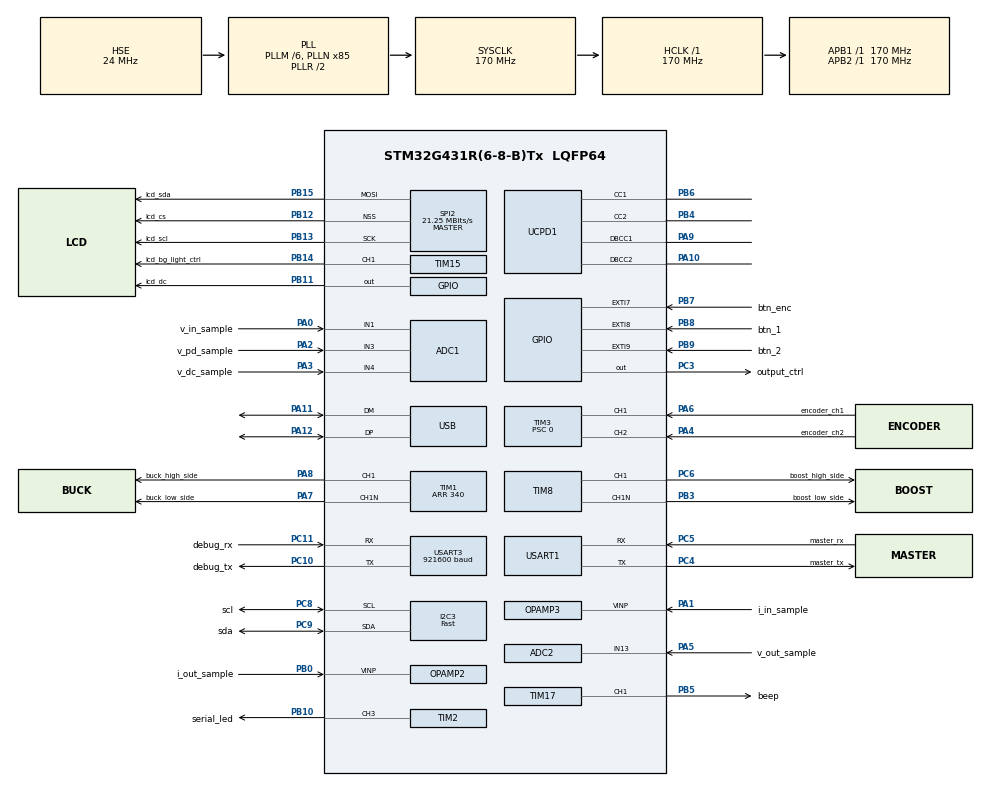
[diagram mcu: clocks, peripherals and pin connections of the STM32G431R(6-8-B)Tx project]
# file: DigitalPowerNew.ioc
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ADC1.Channel-2\#ChannelRegularConversion=ADC_CHANNEL_1
ADC1.Channel-3\#ChannelRegularConversion=ADC_CHANNEL_3
ADC1.Channel-4\#ChannelRegularConversion=ADC_CHANNEL_4
ADC1.ContinuousConvMode=ENABLE
ADC1.DMAContinuousRequests=ENABLE
ADC1.DataAlign=ADC_DATAALIGN_RIGHT
ADC1.EOCSelection=ADC_EOC_SEQ_CONV
ADC1.NbrOfConversion=3
ADC1.NbrOfConversionFlag=1
ADC1.OffsetNumber-2\#ChannelRegularConversion=ADC_OFFSET_NONE
ADC1.OffsetNumber-3\#ChannelRegularConversion=ADC_OFFSET_NONE
ADC1.OffsetNumber-4\#ChannelRegularConversion=ADC_OFFSET_NONE
ADC1.OversamplingMode=ENABLE
ADC1.Rank-2\#ChannelRegularConversion=1
ADC1.Rank-3\#ChannelRegularConversion=2
ADC1.Rank-4\#ChannelRegularConversion=3
ADC1.Ratio=ADC_OVERSAMPLING_RATIO_16
ADC1.RightBitShift=ADC_RIGHTBITSHIFT_NONE
ADC1.SamplingTime-2\#ChannelRegularConversion=ADC_SAMPLETIME_24CYCLES_5
ADC1.SamplingTime-3\#ChannelRegularConversion=ADC_SAMPLETIME_24CYCLES_5
ADC1.SamplingTime-4\#ChannelRegularConversion=ADC_SAMPLETIME_24CYCLES_5
ADC1.master=1
ADC2.Channel-1\#ChannelRegularConversion=ADC_CHANNEL_13
ADC2.Channel-2\#ChannelRegularConversion=ADC_CHANNEL_VOPAMP2
ADC2.Channel-3\#ChannelRegularConversion=ADC_CHANNEL_VOPAMP3_ADC2
ADC2.ClockPrescaler=ADC_CLOCK_SYNC_PCLK_DIV4
ADC2.ContinuousConvMode=ENABLE
ADC2.DMAContinuousRequests=ENABLE
ADC2.DataAlign=ADC_DATAALIGN_RIGHT
ADC2.EOCSelection=ADC_EOC_SEQ_CONV
ADC2.NbrOfConversion=3
ADC2.NbrOfConversionFlag=1
ADC2.OffsetNumber-1\#ChannelRegularConversion=ADC_OFFSET_NONE
ADC2.OffsetNumber-2\#ChannelRegularConversion=ADC_OFFSET_NONE
ADC2.OffsetNumber-3\#ChannelRegularConversion=ADC_OFFSET_NONE
ADC2.OversamplingMode=ENABLE
ADC2.Rank-1\#ChannelRegularConversion=1
ADC2.Rank-2\#ChannelRegularConversion=2
ADC2.Rank-3\#ChannelRegularConversion=3
ADC2.Ratio=ADC_OVERSAMPLING_RATIO_16
ADC2.RightBitShift=ADC_RIGHTBITSHIFT_NONE
ADC2.SamplingTime-1\#ChannelRegularConversion=ADC_SAMPLETIME_24CYCLES_5
ADC2.SamplingTime-2\#ChannelRegularConversion=ADC_SAMPLETIME_24CYCLES_5
ADC2.SamplingTime-3\#ChannelRegularConversion=ADC_SAMPLETIME_24CYCLES_5
DAC1.DAC_Channel-DAC_OUT2_Int=DAC_CHANNEL_2
DAC3.DAC_Channel-DAC_OUT2_Int=DAC_CHANNEL_2
Dma.ADC1.1.Direction=DMA_PERIPH_TO_MEMORY
Dma.ADC1.1.EventEnable=DISABLE
Dma.ADC1.1.Instance=DMA1_Channel2
Dma.ADC1.1.MemDataAlignment=DMA_MDATAALIGN_HALFWORD
Dma.ADC1.1.MemInc=DMA_MINC_ENABLE
Dma.ADC1.1.Mode=DMA_CIRCULAR
Dma.ADC1.1.PeriphDataAlignment=DMA_PDATAALIGN_HALFWORD
Dma.ADC1.1.PeriphInc=DMA_PINC_DISABLE
Dma.ADC1.1.Polarity=HAL_DMAMUX_REQ_GEN_RISING
Dma.ADC1.1.Priority=DMA_PRIORITY_LOW
Dma.ADC1.1.RequestNumber=1
Dma.ADC1.1.SignalID=NONE
Dma.ADC1.1.SyncEnable=DISABLE
Dma.ADC1.1.SyncPolarity=HAL_DMAMUX_SYNC_NO_EVENT
Dma.ADC1.1.SyncRequestNumber=1
Dma.ADC1.1.SyncSignalID=NONE
Dma.ADC2.2.Direction=DMA_PERIPH_TO_MEMORY
Dma.ADC2.2.EventEnable=DISABLE
Dma.ADC2.2.Instance=DMA1_Channel3
Dma.ADC2.2.MemDataAlignment=DMA_MDATAALIGN_HALFWORD
Dma.ADC2.2.MemInc=DMA_MINC_ENABLE
Dma.ADC2.2.Mode=DMA_CIRCULAR
Dma.ADC2.2.PeriphDataAlignment=DMA_PDATAALIGN_HALFWORD
Dma.ADC2.2.PeriphInc=DMA_PINC_DISABLE
Dma.ADC2.2.Polarity=HAL_DMAMUX_REQ_GEN_RISING
Dma.ADC2.2.Priority=DMA_PRIORITY_LOW
Dma.ADC2.2.RequestNumber=1
Dma.ADC2.2.SignalID=NONE
Dma.ADC2.2.SyncEnable=DISABLE
Dma.ADC2.2.SyncPolarity=HAL_DMAMUX_SYNC_NO_EVENT
Dma.ADC2.2.SyncRequestNumber=1
Dma.ADC2.2.SyncSignalID=NONE
Dma.Request0=TIM2_CH3
Dma.Request1=ADC1
Dma.Request2=ADC2
Dma.Request3=UCPD1_RX
Dma.Request4=UCPD1_TX
Dma.Request5=SPI2_TX
Dma.Request6=USART3_TX
Dma.SPI2_TX.5.Direction=DMA_MEMORY_TO_PERIPH
Dma.SPI2_TX.5.EventEnable=DISABLE
Dma.SPI2_TX.5.Instance=DMA1_Channel6
Dma.SPI2_TX.5.MemDataAlignment=DMA_MDATAALIGN_BYTE
Dma.SPI2_TX.5.MemInc=DMA_MINC_ENABLE
Dma.SPI2_TX.5.Mode=DMA_NORMAL
Dma.SPI2_TX.5.PeriphDataAlignment=DMA_PDATAALIGN_BYTE
Dma.SPI2_TX.5.PeriphInc=DMA_PINC_DISABLE
Dma.SPI2_TX.5.Polarity=HAL_DMAMUX_REQ_GEN_RISING
Dma.SPI2_TX.5.Priority=DMA_PRIORITY_LOW
Dma.SPI2_TX.5.RequestNumber=1
Dma.SPI2_TX.5.SignalID=NONE
Dma.SPI2_TX.5.SyncEnable=DISABLE
Dma.SPI2_TX.5.SyncPolarity=HAL_DMAMUX_SYNC_NO_EVENT
Dma.SPI2_TX.5.SyncRequestNumber=1
Dma.SPI2_TX.5.SyncSignalID=NONE
Dma.TIM2_CH3.0.Direction=DMA_MEMORY_TO_PERIPH
Dma.TIM2_CH3.0.EventEnable=DISABLE
Dma.TIM2_CH3.0.Instance=DMA1_Channel1
Dma.TIM2_CH3.0.MemDataAlignment=DMA_MDATAALIGN_HALFWORD
Dma.TIM2_CH3.0.MemInc=DMA_MINC_ENABLE
Dma.TIM2_CH3.0.Mode=DMA_NORMAL
Dma.TIM2_CH3.0.PeriphDataAlignment=DMA_PDATAALIGN_WORD
Dma.TIM2_CH3.0.PeriphInc=DMA_PINC_DISABLE
Dma.TIM2_CH3.0.Polarity=HAL_DMAMUX_REQ_GEN_RISING
Dma.TIM2_CH3.0.Priority=DMA_PRIORITY_LOW
Dma.TIM2_CH3.0.RequestNumber=1
Dma.TIM2_CH3.0.SignalID=NONE
Dma.TIM2_CH3.0.SyncEnable=DISABLE
Dma.TIM2_CH3.0.SyncPolarity=HAL_DMAMUX_SYNC_NO_EVENT
Dma.TIM2_CH3.0.SyncRequestNumber=1
Dma.TIM2_CH3.0.SyncSignalID=NONE
Dma.UCPD1_RX.3.Direction=DMA_PERIPH_TO_MEMORY
Dma.UCPD1_RX.3.EventEnable=DISABLE
Dma.UCPD1_RX.3.Instance=DMA1_Channel4
Dma.UCPD1_RX.3.MemDataAlignment=DMA_MDATAALIGN_BYTE
Dma.UCPD1_RX.3.MemInc=DMA_MINC_ENABLE
Dma.UCPD1_RX.3.Mode=DMA_NORMAL
Dma.UCPD1_RX.3.PeriphDataAlignment=DMA_PDATAALIGN_BYTE
Dma.UCPD1_RX.3.PeriphInc=DMA_PINC_DISABLE
Dma.UCPD1_RX.3.Polarity=HAL_DMAMUX_REQ_GEN_RISING
Dma.UCPD1_RX.3.Priority=DMA_PRIORITY_LOW
Dma.UCPD1_RX.3.RequestNumber=1
Dma.UCPD1_RX.3.SignalID=NONE
Dma.UCPD1_RX.3.SyncEnable=DISABLE
Dma.UCPD1_RX.3.SyncPolarity=HAL_DMAMUX_SYNC_NO_EVENT
Dma.UCPD1_RX.3.SyncRequestNumber=1
Dma.UCPD1_RX.3.SyncSignalID=NONE
Dma.UCPD1_TX.4.Direction=DMA_MEMORY_TO_PERIPH
Dma.UCPD1_TX.4.EventEnable=DISABLE
Dma.UCPD1_TX.4.Instance=DMA1_Channel5
Dma.UCPD1_TX.4.MemDataAlignment=DMA_MDATAALIGN_BYTE
Dma.UCPD1_TX.4.MemInc=DMA_MINC_ENABLE
Dma.UCPD1_TX.4.Mode=DMA_NORMAL
Dma.UCPD1_TX.4.PeriphDataAlignment=DMA_PDATAALIGN_BYTE
Dma.UCPD1_TX.4.PeriphInc=DMA_PINC_DISABLE
Dma.UCPD1_TX.4.Polarity=HAL_DMAMUX_REQ_GEN_RISING
Dma.UCPD1_TX.4.Priority=DMA_PRIORITY_LOW
Dma.UCPD1_TX.4.RequestNumber=1
Dma.UCPD1_TX.4.SignalID=NONE
Dma.UCPD1_TX.4.SyncEnable=DISABLE
Dma.UCPD1_TX.4.SyncPolarity=HAL_DMAMUX_SYNC_NO_EVENT
Dma.UCPD1_TX.4.SyncRequestNumber=1
Dma.UCPD1_TX.4.SyncSignalID=NONE
Dma.USART3_TX.6.Direction=DMA_MEMORY_TO_PERIPH
Dma.USART3_TX.6.EventEnable=DISABLE
Dma.USART3_TX.6.Instance=DMA2_Channel1
Dma.USART3_TX.6.MemDataAlignment=DMA_MDATAALIGN_BYTE
Dma.USART3_TX.6.MemInc=DMA_MINC_ENABLE
Dma.USART3_TX.6.Mode=DMA_NORMAL
Dma.USART3_TX.6.PeriphDataAlignment=DMA_PDATAALIGN_BYTE
Dma.USART3_TX.6.PeriphInc=DMA_PINC_DISABLE
Dma.USART3_TX.6.Polarity=HAL_DMAMUX_REQ_GEN_RISING
Dma.USART3_TX.6.Priority=DMA_PRIORITY_LOW
Dma.USART3_TX.6.RequestNumber=1
Dma.USART3_TX.6.SignalID=NONE
Dma.USART3_TX.6.SyncEnable=DISABLE
Dma.USART3_TX.6.SyncPolarity=HAL_DMAMUX_SYNC_NO_EVENT
Dma.USART3_TX.6.SyncRequestNumber=1
Dma.USART3_TX.6.SyncSignalID=NONE
FREERTOS.HEAP_NUMBER=3
FREERTOS.MEMORY_ALLOCATION=1
FREERTOS.Queues01=consoleBufferQueue,512,char,0,Static,consoleBufferQueueBuffer,consoleBufferQueueControlBlock;uiInputEventQueue,32,uint8_t,0,Static,uiInputEventQueueBuffer,uiInputEventQueueControlBlock
FREERTOS.Tasks01=userMain,8,256,user_main,As weak,NULL,Static,userMainBuffer,userMainControlBlock;guiThread,8,1024,gui_thread,As external,NULL,Static,guiThreadBuffer,guiThreadControlBlock;usbThread,8,512,usb_thread,As external,NULL,Static,usbThreadBuffer,usbThreadControlBlock
FREERTOS.Timers01=powerControlTimer,power_control_timer_handle,osTimerPeriodic,As external,NULL,Static,powerControlTimerControlBlock
FREERTOS.configCHECK_FOR_STACK_OVERFLOW=2
FREERTOS.configENABLE_FPU=1
FREERTOS.configLIBRARY_MAX_SYSCALL_INTERRUPT_PRIORITY=3
FREERTOS.configTIMER_TASK_PRIORITY=55
FREERTOS.copyHeapFile=1
I2C3.DualAddressMode=I2C_DUALADDRESS_DISABLE
I2C3.I2C_Speed_Mode=I2C_Fast
I2C3.Timing=0x40621236
Mcu.Family=STM32G4
Mcu.Name=STM32G431R(6-8-B)Tx
Mcu.Package=LQFP64
NVIC.DMA1_Channel1_IRQn=true\:3\:0\:false\:false\:true\:true\:false\:true\:true
NVIC.DMA1_Channel2_IRQn=true\:3\:0\:false\:false\:true\:true\:false\:true\:true
NVIC.DMA1_Channel3_IRQn=true\:3\:0\:false\:false\:true\:true\:false\:true\:true
NVIC.DMA1_Channel4_IRQn=true\:3\:0\:false\:false\:true\:true\:false\:true\:true
NVIC.DMA1_Channel5_IRQn=true\:3\:0\:false\:false\:true\:true\:false\:true\:true
NVIC.DMA1_Channel6_IRQn=true\:3\:0\:false\:false\:true\:true\:false\:true\:true
NVIC.DMA2_Channel1_IRQn=true\:3\:0\:false\:false\:true\:true\:false\:true\:true
NVIC.EXTI9_5_IRQn=true\:3\:0\:false\:false\:true\:true\:true\:true\:true
NVIC.I2C3_ER_IRQn=true\:3\:0\:false\:false\:true\:true\:true\:true\:true
NVIC.I2C3_EV_IRQn=true\:3\:0\:false\:false\:true\:true\:true\:true\:true
NVIC.PriorityGroup=NVIC_PRIORITYGROUP_4
NVIC.TIM1_UP_TIM16_IRQn=true\:3\:0\:false\:false\:true\:true\:true\:true\:true
NVIC.TIM3_IRQn=true\:3\:0\:false\:false\:true\:true\:true\:true\:true
NVIC.TIM6_DAC_IRQn=true\:3\:0\:false\:false\:true\:true\:true\:true\:true
NVIC.TIM7_IRQn=true\:15\:0\:false\:false\:true\:false\:false\:true\:true
NVIC.TimeBase=TIM7_IRQn
NVIC.TimeBaseIP=TIM7
NVIC.UCPD1_IRQn=true\:3\:0\:false\:false\:true\:true\:true\:false\:true
NVIC.USART1_IRQn=true\:3\:0\:false\:false\:true\:true\:true\:true\:true
NVIC.USART3_IRQn=true\:3\:0\:false\:false\:true\:true\:true\:true\:true
NVIC.USB_LP_IRQn=true\:3\:0\:false\:false\:true\:true\:false\:true\:true
OPAMP2.PowerMode=OPAMP_POWERMODE_HIGHSPEED
OPAMP3.PowerMode=OPAMP_POWERMODE_HIGHSPEED
PA0.GPIO_Label=v_in_sample
PA0.Mode=IN1-Single-Ended
PA0.Signal=ADC1_IN1
PA1.GPIO_Label=i_in_sample
PA1.Mode=PGA_Internally_Connected
PA1.Signal=OPAMP3_VINP
PA10.Mode=EnableDeadBattery
PA10.Signal=UCPD1_DBCC2
PA11.Mode=Device
PA11.Signal=USB_DM
PA12.Mode=Device
PA12.Signal=USB_DP
PA13.Mode=Serial_Wire
PA13.Signal=SYS_JTMS-SWDIO
PA14.Mode=Serial_Wire
PA14.Signal=SYS_JTCK-SWCLK
PA2.GPIO_Label=v_pd_sample
PA2.Mode=IN3-Single-Ended
PA2.Signal=ADC1_IN3
PA3.GPIO_Label=v_dc_sample
PA3.Signal=SharedAnalog_PA3
PA4.GPIO_Label=encoder_ch2
PA4.GPIO_PuPd=GPIO_PULLDOWN
PA4.Signal=S_TIM3_CH2
PA5.GPIO_Label=v_out_sample
PA5.Mode=IN13-Single-Ended
PA5.Signal=ADC2_IN13
PA6.GPIO_Label=encoder_ch1
PA6.GPIO_PuPd=GPIO_PULLDOWN
PA6.Signal=S_TIM3_CH1
PA7.GPIO_Label=buck_low_side
PA7.GPIO_Speed=GPIO_SPEED_FREQ_VERY_HIGH
PA7.Mode=PWM Generation1 CH1 CH1N
PA7.Signal=TIM1_CH1N
PA8.GPIO_Label=buck_high_side
PA8.GPIO_Speed=GPIO_SPEED_FREQ_VERY_HIGH
PA8.Signal=S_TIM1_CH1
PA9.Mode=EnableDeadBattery
PA9.Signal=UCPD1_DBCC1
PB0.GPIO_Label=i_out_sample
PB0.Signal=SharedAnalog_PB0
PB10.GPIO_Label=serial_led
PB10.GPIO_Speed=GPIO_SPEED_FREQ_VERY_HIGH
PB10.Signal=S_TIM2_CH3
PB11.GPIO_Label=lcd_dc
PB11.GPIO_Speed=GPIO_SPEED_FREQ_VERY_HIGH
PB11.Signal=GPIO_Output
PB12.GPIO_Label=lcd_cs
PB12.GPIO_Speed=GPIO_SPEED_FREQ_MEDIUM
PB12.Mode=NSS_Signal_Hard_Output
PB12.Signal=SPI2_NSS
PB13.GPIO_Label=lcd_scl
PB13.GPIO_Speed=GPIO_SPEED_FREQ_MEDIUM
PB13.Mode=TX_Only_Simplex_Unidirect_Master
PB13.Signal=SPI2_SCK
PB14.GPIO_Label=lcd_bg_light_ctrl
PB14.Signal=S_TIM15_CH1
PB15.GPIO_Label=lcd_sda
PB15.GPIO_Speed=GPIO_SPEED_FREQ_MEDIUM
PB15.Mode=TX_Only_Simplex_Unidirect_Master
PB15.Signal=SPI2_MOSI
PB3.GPIO_Label=boost_low_side
PB3.GPIO_Speed=GPIO_SPEED_FREQ_VERY_HIGH
PB3.Mode=PWM Generation1 CH1 CH1N
PB3.Signal=TIM8_CH1N
PB4.Mode=Sink_AllSignals
PB4.Signal=UCPD1_CC2
PB5.GPIO_Label=beep
PB5.GPIO_Speed=GPIO_SPEED_FREQ_VERY_HIGH
PB5.Signal=S_TIM17_CH1
PB6.Mode=Sink_AllSignals
PB6.Signal=UCPD1_CC1
PB7.GPIO_Label=btn_enc
PB7.GPIO_ModeDefaultEXTI=GPIO_MODE_IT_RISING_FALLING
PB7.GPIO_PuPd=GPIO_PULLDOWN
PB7.Signal=GPXTI7
PB8-BOOT0.GPIO_Label=btn_1
PB8-BOOT0.GPIO_ModeDefaultEXTI=GPIO_MODE_IT_RISING_FALLING
PB8-BOOT0.GPIO_PuPd=GPIO_PULLDOWN
PB8-BOOT0.Signal=GPXTI8
PB9.GPIO_Label=btn_2
PB9.GPIO_ModeDefaultEXTI=GPIO_MODE_IT_RISING_FALLING
PB9.GPIO_PuPd=GPIO_PULLDOWN
PB9.Signal=GPXTI9
PC10.GPIO_Label=debug_tx
PC10.Mode=Asynchronous
PC10.Signal=USART3_TX
PC11.GPIO_Label=debug_rx
PC11.Mode=Asynchronous
PC11.Signal=USART3_RX
PC3.GPIO_Label=output_ctrl
PC3.Signal=GPIO_Output
PC4.GPIO_Label=master_tx
PC4.Mode=Asynchronous
PC4.Signal=USART1_TX
PC5.GPIO_Label=master_rx
PC5.Mode=Asynchronous
PC5.Signal=USART1_RX
PC6.GPIO_Label=boost_high_side
PC6.GPIO_Speed=GPIO_SPEED_FREQ_VERY_HIGH
PC6.Signal=S_TIM8_CH1
PC8.GPIO_Label=scl
PC8.GPIO_Pu=GPIO_PULLUP
PC8.Mode=I2C
PC8.Signal=I2C3_SCL
PC9.GPIO_Label=sda
PC9.GPIO_Pu=GPIO_PULLUP
PC9.Mode=I2C
PC9.Signal=I2C3_SDA
PF0-OSC_IN.Mode=HSE-External-Oscillator
PF0-OSC_IN.Signal=RCC_OSC_IN
PF1-OSC_OUT.Mode=HSE-External-Oscillator
PF1-OSC_OUT.Signal=RCC_OSC_OUT
ProjectManager.HeapSize=0x2000
ProjectManager.StackSize=0x100
ProjectManager.TargetToolchain=MDK-ARM V5.32
RCC.ADC12Freq_Value=170000000
RCC.AHBFreq_Value=170000000
RCC.APB1Freq_Value=170000000
RCC.APB1TimFreq_Value=170000000
RCC.APB2Freq_Value=170000000
RCC.APB2TimFreq_Value=170000000
RCC.CK48CLockSelection=RCC_USBCLKSOURCE_HSI48
RCC.CortexFreq_Value=170000000
RCC.EXTERNAL_CLOCK_VALUE=12288000
RCC.EnbaleCSS=true
RCC.HCLKFreq_Value=170000000
RCC.HSE_VALUE=24000000
RCC.HSI48_VALUE=48000000
RCC.HSI_VALUE=16000000
RCC.LSE_VALUE=32768
RCC.PLLM=RCC_PLLM_DIV6
RCC.PLLN=85
RCC.PLLQ=RCC_PLLQ_DIV4
RCC.PLLSourceVirtual=RCC_PLLSOURCE_HSE
RCC.SYSCLKFreq_VALUE=170000000
RCC.SYSCLKSource=RCC_SYSCLKSOURCE_PLLCLK
RCC.USBFreq_Value=48000000
RCC.VCOOutputFreq_Value=340000000
SH.S_TIM15_CH1.0=TIM15_CH1,PWM Generation1 CH1
SH.S_TIM17_CH1.0=TIM17_CH1,PWM Generation1 CH1
SH.S_TIM1_CH1.0=TIM1_CH1,PWM Generation1 CH1 CH1N
SH.S_TIM2_CH3.0=TIM2_CH3,PWM Generation3 CH3
SH.S_TIM3_CH1.0=TIM3_CH1,Encoder_Interface
SH.S_TIM3_CH2.0=TIM3_CH2,Encoder_Interface
SH.S_TIM8_CH1.0=TIM8_CH1,PWM Generation1 CH1 CH1N
SH.SharedAnalog_PA3.0=COMP2_INP
SH.SharedAnalog_PA3.1=ADC1_IN4,IN4-Single-Ended
SH.SharedAnalog_PB0.0=OPAMP2_VINP,PGA_Internally_Connected
SH.SharedAnalog_PB0.1=COMP4_INP,INP
SPI2.BaudRatePrescaler=SPI_BAUDRATEPRESCALER_8
SPI2.CalculateBaudRate=21.25 MBits/s
SPI2.DataSize=SPI_DATASIZE_8BIT
SPI2.Direction=SPI_DIRECTION_2LINES
SPI2.Mode=SPI_MODE_MASTER
SPI2.NSSPMode=SPI_NSS_PULSE_ENABLE
SPI2.VirtualNSS=VM_NSSHARD
SPI2.VirtualType=VM_MASTER
TIM1.AutoReloadPreload=TIM_AUTORELOAD_PRELOAD_ENABLE
TIM1.Channel-PWM\ Generation1\ CH1\ CH1N=TIM_CHANNEL_1
TIM1.DeadTime=2
TIM1.Dithering=Enable
TIM1.Fractionnal_PeriodDither=14
TIM1.Integer_PeriodDither=340
TIM1.Integer_PulseDither_1=4095
TIM1.OCNPolarity_1=TIM_OCNPOLARITY_LOW
TIM1.PeriodNoDither=340
TIM1.TIM_MasterOutputTrigger=TIM_TRGO_ENABLE
TIM1.TIM_MasterSlaveMode=TIM_MASTERSLAVEMODE_ENABLE
TIM15.Channel-PWM\ Generation1\ CH1=TIM_CHANNEL_1
TIM15.OCPolarity_1=TIM_OCPOLARITY_LOW
TIM17.AutoReloadPreload=TIM_AUTORELOAD_PRELOAD_DISABLE
TIM17.Channel=TIM_CHANNEL_1
TIM17.PeriodNoDither=255
TIM17.PulseNoDither_1=0
TIM2.AutoReloadPreload=TIM_AUTORELOAD_PRELOAD_ENABLE
TIM2.Channel-PWM\ Generation3\ CH3=TIM_CHANNEL_3
TIM2.PeriodNoDither=170
TIM2.Prescaler=0
TIM3.AutoReloadPreload=TIM_AUTORELOAD_PRELOAD_ENABLE
TIM3.EncoderMode=TIM_ENCODERMODE_TI12
TIM3.PeriodNoDither=1
TIM3.Prescaler=0
TIM6.AutoReloadPreload=TIM_AUTORELOAD_PRELOAD_ENABLE
TIM6.Prescaler=128
TIM8.AsymmetricalDeadTime=DISABLE
TIM8.AutoReloadPreload=TIM_AUTORELOAD_PRELOAD_ENABLE
TIM8.Channel-PWM\ Generation1\ CH1\ CH1N=TIM_CHANNEL_1
TIM8.DeadTime=2
TIM8.DeadTimePreload=DISABLE
TIM8.Dithering=Enable
TIM8.Fractionnal_PeriodDither=14
TIM8.Integer_PeriodDither=340
TIM8.Integer_PulseDither_1=4095
TIM8.OCNPolarity_1=TIM_OCNPOLARITY_LOW
TIM8.TIM_MasterOutputTrigger=TIM_TRGO_RESET
TIM8.TIM_MasterSlaveMode=TIM_MASTERSLAVEMODE_DISABLE
USART1.VirtualMode-Asynchronous=VM_ASYNC
USART3.BaudRate=921600
USART3.FIFOMode=FIFOMODE_DISABLE
USART3.Mode=MODE_TX
USART3.SwapParam=ADVFEATURE_SWAP_ENABLE
USART3.VirtualMode-Asynchronous=VM_ASYNC
USBPD.Is_GetPPSStatus_Supported_P0=USBPD_TRUE
USBPD.PORT0_NB_SINKPDO=1
USBPD.USBPD_PDO_FIXED_USBCOMM_P0=USBPD_PDO_FIXED_USBCOMM_SUPPORTED
USB_DEVICE.CLASS_NAME_FS=CUSTOM_HID
USB_DEVICE.VirtualMode=CustomHid
USB_DEVICE.VirtualModeFS=Custom_Hid_FS
VP_ADC2_OPAMP_INTERNAL2.Mode=IN-OPAMP2
VP_ADC2_OPAMP_INTERNAL3.Mode=IN-OPAMP3
VP_COMP4_VS_DAC3OUT2.Mode=INM_DAC3OUT2
VP_DAC1_VS_DACI1.Mode=DAC_OUT1_Int
VP_DAC1_VS_DACI2.Mode=DAC_OUT2_Int
VP_DAC3_VS_DACI2.Mode=DAC_OUT2_Int
VP_FREERTOS_VS_CMSIS_V2.Mode=CMSIS_V2
VP_SYS_VS_DBSignals.Mode=DisableDeadBatterySignals
VP_SYS_VS_tim7.Mode=TIM7
VP_SYS_V_VREFBUF.Mode=ExternalMode
VP_TIM17_VS_ClockSourceINT.Mode=Enable_Timer
VP_TIM1_VS_ClockSourceINT.Mode=Internal
VP_TIM6_VS_ClockSourceINT.Mode=Enable_Timer
VP_TIM8_VS_ClockSourceINT.Mode=Internal
VP_TIM8_VS_ClockSourceITR.Mode=TriggerSource_ITR0
VP_TIM8_VS_ControllerModeTrigger.Mode=Trigger Mode
VP_USBPD_VS_PD3CFG1.Mode=PD3_Config1
VP_USBPD_VS_USBPD1.Mode=USBPD_P0
VP_USBPD_VS_usbpd_tim4.Mode=TIM4
VP_USB_DEVICE_VS_USB_DEVICE_CUSTOM_HID_FS.Mode=CUSTOM_HID_FS
board=custom

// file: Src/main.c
/* USER CODE BEGIN Header */
/**
  ******************************************************************************
  * @file           : main.c
  * @brief          : Main program body
  ******************************************************************************
  * @attention
  *
  * Copyright (c) 2025 STMicroelectronics.
  * All rights reserved.
  *
  * This software is licensed under terms that can be found in the LICENSE file
  * in the root directory of this software component.
  * If no LICENSE file comes with this software, it is provided AS-IS.
  *
  ******************************************************************************
  */
/* USER CODE END Header */
#include "main.h"
#include "cmsis_os.h"
#include "adc.h"
#include "comp.h"
#include "dac.h"
#include "dma.h"
#include "i2c.h"
#include "opamp.h"
#include "spi.h"
#include "tim.h"
#include "ucpd.h"
#include "usart.h"
#include "usbpd.h"
#include "usb_device.h"
#include "gpio.h"

void SystemClock_Config(void);
void MX_FREERTOS_Init(void);

int main(void)
{

  /* MCU Configuration--------------------------------------------------------*/

  /* Reset of all peripherals, Initializes the Flash interface and the Systick. */
  HAL_Init();

  /* Configure the system clock */
  SystemClock_Config();

  /* Initialize all configured peripherals */
  MX_GPIO_Init();
  MX_DMA_Init();
  MX_ADC1_Init();
  MX_ADC2_Init();
  MX_COMP4_Init();
  MX_DAC1_Init();
  MX_DAC3_Init();
  MX_I2C3_Init();
  MX_OPAMP2_Init();
  MX_OPAMP3_Init();
  MX_SPI2_Init();
  MX_TIM1_Init();
  MX_TIM2_Init();
  MX_TIM3_Init();
  MX_TIM8_Init();
  MX_TIM15_Init();
  MX_TIM17_Init();
  MX_UCPD1_Init();
  MX_USART1_UART_Init();
  MX_USART3_UART_Init();
  MX_TIM6_Init();
  /* USER CODE BEGIN 2 */
  DBGMCU->APB1FZR1 |= DBGMCU_APB1FZR1_DBG_TIM6_STOP;
  /* USER CODE END 2 */

  /* Init scheduler */
  osKernelInitialize();
  /* USBPD initialisation ---------------------------------*/
  MX_USBPD_Init();

  /* Call init function for freertos objects (in cmsis_os2.c) */
  MX_FREERTOS_Init();

  /* Start scheduler */
  osKernelStart();

  /* We should never get here as control is now taken by the scheduler */

  /* Infinite loop */
  while (1)
  {

  }
}

void SystemClock_Config(void)
{
  RCC_OscInitTypeDef RCC_OscInitStruct = {0};
  RCC_ClkInitTypeDef RCC_ClkInitStruct = {0};

  /** Configure the main internal regulator output voltage
  */
  HAL_PWREx_ControlVoltageScaling(PWR_REGULATOR_VOLTAGE_SCALE1_BOOST);

  /** Initializes the RCC Oscillators according to the specified parameters
  * in the RCC_OscInitTypeDef structure.
  */
  RCC_OscInitStruct.OscillatorType = RCC_OSCILLATORTYPE_HSI|RCC_OSCILLATORTYPE_HSI48
                              |RCC_OSCILLATORTYPE_HSE;
  RCC_OscInitStruct.HSEState = RCC_HSE_ON;
  RCC_OscInitStruct.HSIState = RCC_HSI_ON;
  RCC_OscInitStruct.HSICalibrationValue = RCC_HSICALIBRATION_DEFAULT;
  RCC_OscInitStruct.HSI48State = RCC_HSI48_ON;
  RCC_OscInitStruct.PLL.PLLState = RCC_PLL_ON;
  RCC_OscInitStruct.PLL.PLLSource = RCC_PLLSOURCE_HSE;
  RCC_OscInitStruct.PLL.PLLM = RCC_PLLM_DIV6;
  RCC_OscInitStruct.PLL.PLLN = 85;
  RCC_OscInitStruct.PLL.PLLP = RCC_PLLP_DIV2;
  RCC_OscInitStruct.PLL.PLLQ = RCC_PLLQ_DIV4;
  RCC_OscInitStruct.PLL.PLLR = RCC_PLLR_DIV2;
  if (HAL_RCC_OscConfig(&RCC_OscInitStruct) != HAL_OK)
  {
    Error_Handler();
  }

  /** Initializes the CPU, AHB and APB buses clocks
  */
  RCC_ClkInitStruct.ClockType = RCC_CLOCKTYPE_HCLK|RCC_CLOCKTYPE_SYSCLK
                              |RCC_CLOCKTYPE_PCLK1|RCC_CLOCKTYPE_PCLK2;
  RCC_ClkInitStruct.SYSCLKSource = RCC_SYSCLKSOURCE_PLLCLK;
  RCC_ClkInitStruct.AHBCLKDivider = RCC_SYSCLK_DIV1;
  RCC_ClkInitStruct.APB1CLKDivider = RCC_HCLK_DIV1;
  RCC_ClkInitStruct.APB2CLKDivider = RCC_HCLK_DIV1;

  if (HAL_RCC_ClockConfig(&RCC_ClkInitStruct, FLASH_LATENCY_4) != HAL_OK)
  {
    Error_Handler();
  }

  /** Enables the Clock Security System
  */
  HAL_RCC_EnableCSS();
}

/* USER CODE BEGIN 4 */
__WEAK
/* USER CODE END 4 */

void HAL_TIM_PeriodElapsedCallback(TIM_HandleTypeDef *htim)
{
  if (htim->Instance == TIM7) {
    HAL_IncTick();
  }
}

void Error_Handler(void)
{
  /* USER CODE BEGIN Error_Handler_Debug */
  /* User can add his own implementation to report the HAL error return state */
  __disable_irq();
  __asm("BKPT 0");
  while (1)
  {
  }
  /* USER CODE END Error_Handler_Debug */
}

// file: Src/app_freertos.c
/* USER CODE BEGIN Header */
/**
  ******************************************************************************
  * File Name          : app_freertos.c
  * Description        : Code for freertos applications
  ******************************************************************************
  * @attention
  *
  * Copyright (c) 2025 STMicroelectronics.
  * All rights reserved.
  *
  * This software is licensed under terms that can be found in the LICENSE file
  * in the root directory of this software component.
  * If no LICENSE file comes with this software, it is provided AS-IS.
  *
  ******************************************************************************
  */
/* USER CODE END Header */

#include "FreeRTOS.h"
#include "task.h"
#include "main.h"
#include "cmsis_os.h"

/* USER CODE BEGIN Includes */

#include "usb_device.h"

/* USER CODE END Includes */

typedef StaticTask_t osStaticThreadDef_t;
typedef StaticQueue_t osStaticMessageQDef_t;
typedef StaticTimer_t osStaticTimerDef_t;

/* Definitions for userMain */
osThreadId_t userMainHandle;
uint32_t userMainBuffer[ 256 ];
osStaticThreadDef_t userMainControlBlock;
const osThreadAttr_t userMain_attributes = {
  .name = "userMain",
  .stack_mem = &userMainBuffer[0],
  .stack_size = sizeof(userMainBuffer),
  .cb_mem = &userMainControlBlock,
  .cb_size = sizeof(userMainControlBlock),
  .priority = (osPriority_t) osPriorityLow,
};
/* Definitions for guiThread */
osThreadId_t guiThreadHandle;
uint32_t guiThreadBuffer[ 1024 ];
osStaticThreadDef_t guiThreadControlBlock;
const osThreadAttr_t guiThread_attributes = {
  .name = "guiThread",
  .stack_mem = &guiThreadBuffer[0],
  .stack_size = sizeof(guiThreadBuffer),
  .cb_mem = &guiThreadControlBlock,
  .cb_size = sizeof(guiThreadControlBlock),
  .priority = (osPriority_t) osPriorityLow,
};
/* Definitions for usbThread */
osThreadId_t usbThreadHandle;
uint32_t usbThreadBuffer[ 512 ];
osStaticThreadDef_t usbThreadControlBlock;
const osThreadAttr_t usbThread_attributes = {
  .name = "usbThread",
  .stack_mem = &usbThreadBuffer[0],
  .stack_size = sizeof(usbThreadBuffer),
  .cb_mem = &usbThreadControlBlock,
  .cb_size = sizeof(usbThreadControlBlock),
  .priority = (osPriority_t) osPriorityLow,
};
/* Definitions for consoleBufferQueue */
osMessageQueueId_t consoleBufferQueueHandle;
uint8_t consoleBufferQueueBuffer[ 512 * sizeof( char ) ];
osStaticMessageQDef_t consoleBufferQueueControlBlock;
const osMessageQueueAttr_t consoleBufferQueue_attributes = {
  .name = "consoleBufferQueue",
  .cb_mem = &consoleBufferQueueControlBlock,
  .cb_size = sizeof(consoleBufferQueueControlBlock),
  .mq_mem = &consoleBufferQueueBuffer,
  .mq_size = sizeof(consoleBufferQueueBuffer)
};
/* Definitions for uiInputEventQueue */
osMessageQueueId_t uiInputEventQueueHandle;
uint8_t uiInputEventQueueBuffer[ 32 * sizeof( uint8_t ) ];
osStaticMessageQDef_t uiInputEventQueueControlBlock;
const osMessageQueueAttr_t uiInputEventQueue_attributes = {
  .name = "uiInputEventQueue",
  .cb_mem = &uiInputEventQueueControlBlock,
  .cb_size = sizeof(uiInputEventQueueControlBlock),
  .mq_mem = &uiInputEventQueueBuffer,
  .mq_size = sizeof(uiInputEventQueueBuffer)
};
/* Definitions for powerControlTimer */
osTimerId_t powerControlTimerHandle;
osStaticTimerDef_t powerControlTimerControlBlock;
const osTimerAttr_t powerControlTimer_attributes = {
  .name = "powerControlTimer",
  .cb_mem = &powerControlTimerControlBlock,
  .cb_size = sizeof(powerControlTimerControlBlock),
};

void user_main(void *argument);
extern void gui_thread(void *argument);
extern void usb_thread(void *argument);
extern void power_control_timer_handle(void *argument);

void MX_FREERTOS_Init(void); /* (MISRA C 2004 rule 8.1) */

/* Hook prototypes */
void vApplicationStackOverflowHook(xTaskHandle xTask, signed char *pcTaskName);

/* USER CODE BEGIN 4 */
__weak void vApplicationStackOverflowHook(xTaskHandle xTask, signed char *pcTaskName)
{
   /* Run time stack overflow checking is performed if
   configCHECK_FOR_STACK_OVERFLOW is defined to 1 or 2. This hook function is
   called if a stack overflow is detected. */
}
/* USER CODE END 4 */

void MX_FREERTOS_Init(void) {

  /* Create the timer(s) */
  /* creation of powerControlTimer */
  powerControlTimerHandle = osTimerNew(power_control_timer_handle, osTimerPeriodic, NULL, &powerControlTimer_attributes);

  /* Create the queue(s) */
  /* creation of consoleBufferQueue */
  consoleBufferQueueHandle = osMessageQueueNew (512, sizeof(char), &consoleBufferQueue_attributes);

  /* creation of uiInputEventQueue */
  uiInputEventQueueHandle = osMessageQueueNew (32, sizeof(uint8_t), &uiInputEventQueue_attributes);

  /* Create the thread(s) */
  /* creation of userMain */
  userMainHandle = osThreadNew(user_main, NULL, &userMain_attributes);

  /* creation of guiThread */
  guiThreadHandle = osThreadNew(gui_thread, NULL, &guiThread_attributes);

  /* creation of usbThread */
  usbThreadHandle = osThreadNew(usb_thread, NULL, &usbThread_attributes);

}

__weak void user_main(void *argument)
{
  /* init code for USB_Device */
  MX_USB_Device_Init();
  for(;;)
  {
    osDelay(1);
  }
}
